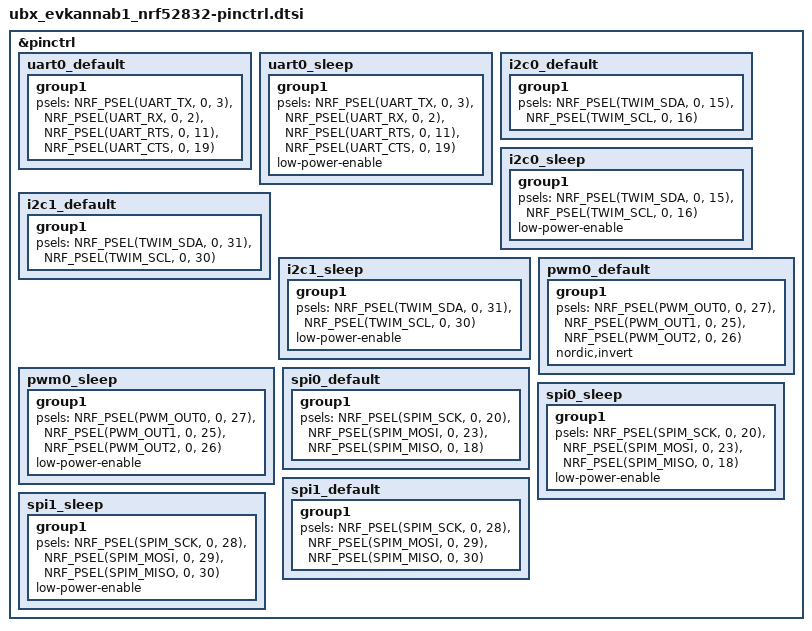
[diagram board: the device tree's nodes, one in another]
/*
 * Copyright (c) 2022 Nordic Semiconductor
 * SPDX-License-Identifier: Apache-2.0
 */

&pinctrl {
	uart0_default: uart0_default {
		group1 {
			psels = <NRF_PSEL(UART_TX, 0, 3)>,
				<NRF_PSEL(UART_RX, 0, 2)>,
				<NRF_PSEL(UART_RTS, 0, 11)>,
				<NRF_PSEL(UART_CTS, 0, 19)>;
		};
	};

	uart0_sleep: uart0_sleep {
		group1 {
			psels = <NRF_PSEL(UART_TX, 0, 3)>,
				<NRF_PSEL(UART_RX, 0, 2)>,
				<NRF_PSEL(UART_RTS, 0, 11)>,
				<NRF_PSEL(UART_CTS, 0, 19)>;
			low-power-enable;
		};
	};

	i2c0_default: i2c0_default {
		group1 {
			psels = <NRF_PSEL(TWIM_SDA, 0, 15)>,
				<NRF_PSEL(TWIM_SCL, 0, 16)>;
		};
	};

	i2c0_sleep: i2c0_sleep {
		group1 {
			psels = <NRF_PSEL(TWIM_SDA, 0, 15)>,
				<NRF_PSEL(TWIM_SCL, 0, 16)>;
			low-power-enable;
		};
	};

	i2c1_default: i2c1_default {
		group1 {
			psels = <NRF_PSEL(TWIM_SDA, 0, 31)>,
				<NRF_PSEL(TWIM_SCL, 0, 30)>;
		};
	};

	i2c1_sleep: i2c1_sleep {
		group1 {
			psels = <NRF_PSEL(TWIM_SDA, 0, 31)>,
				<NRF_PSEL(TWIM_SCL, 0, 30)>;
			low-power-enable;
		};
	};

	pwm0_default: pwm0_default {
		group1 {
			psels = <NRF_PSEL(PWM_OUT0, 0, 27)>,
				<NRF_PSEL(PWM_OUT1, 0, 25)>,
				<NRF_PSEL(PWM_OUT2, 0, 26)>;
			nordic,invert;
		};
	};

	pwm0_sleep: pwm0_sleep {
		group1 {
			psels = <NRF_PSEL(PWM_OUT0, 0, 27)>,
				<NRF_PSEL(PWM_OUT1, 0, 25)>,
				<NRF_PSEL(PWM_OUT2, 0, 26)>;
			low-power-enable;
		};
	};

	spi0_default: spi0_default {
		group1 {
			psels = <NRF_PSEL(SPIM_SCK, 0, 20)>,
				<NRF_PSEL(SPIM_MOSI, 0, 23)>,
				<NRF_PSEL(SPIM_MISO, 0, 18)>;
		};
	};

	spi0_sleep: spi0_sleep {
		group1 {
			psels = <NRF_PSEL(SPIM_SCK, 0, 20)>,
				<NRF_PSEL(SPIM_MOSI, 0, 23)>,
				<NRF_PSEL(SPIM_MISO, 0, 18)>;
			low-power-enable;
		};
	};

	spi1_default: spi1_default {
		group1 {
			psels = <NRF_PSEL(SPIM_SCK, 0, 28)>,
				<NRF_PSEL(SPIM_MOSI, 0, 29)>,
				<NRF_PSEL(SPIM_MISO, 0, 30)>;
		};
	};

	spi1_sleep: spi1_sleep {
		group1 {
			psels = <NRF_PSEL(SPIM_SCK, 0, 28)>,
				<NRF_PSEL(SPIM_MOSI, 0, 29)>,
				<NRF_PSEL(SPIM_MISO, 0, 30)>;
			low-power-enable;
		};
	};

};
